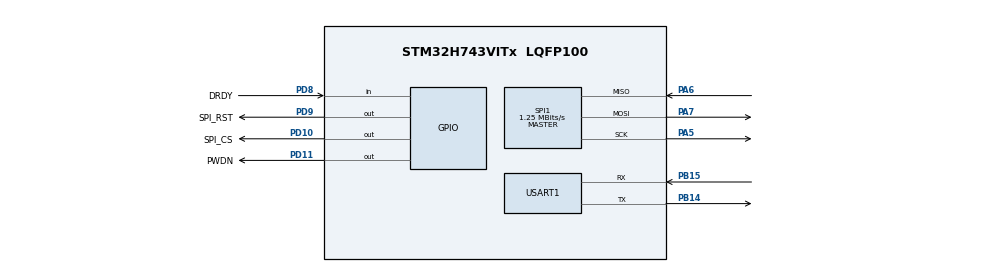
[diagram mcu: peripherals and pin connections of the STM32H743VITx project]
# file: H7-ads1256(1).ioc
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CORTEX_M7.default_mode_Activation=1
Mcu.Family=STM32H7
Mcu.Name=STM32H743VITx
Mcu.Package=LQFP100
NVIC.PriorityGroup=NVIC_PRIORITYGROUP_4
PA13\ (JTMS/SWDIO).Mode=Serial_Wire
PA13\ (JTMS/SWDIO).Signal=DEBUG_JTMS-SWDIO
PA14\ (JTCK/SWCLK).Mode=Serial_Wire
PA14\ (JTCK/SWCLK).Signal=DEBUG_JTCK-SWCLK
PA5.GPIO_Speed=GPIO_SPEED_FREQ_VERY_HIGH
PA5.Mode=Full_Duplex_Master
PA5.Signal=SPI1_SCK
PA6.GPIO_Speed=GPIO_SPEED_FREQ_VERY_HIGH
PA6.Mode=Full_Duplex_Master
PA6.Signal=SPI1_MISO
PA7.GPIO_Speed=GPIO_SPEED_FREQ_VERY_HIGH
PA7.Mode=Full_Duplex_Master
PA7.Signal=SPI1_MOSI
PB14.Mode=Asynchronous
PB14.Signal=USART1_TX
PB15.Mode=Asynchronous
PB15.Signal=USART1_RX
PD10.GPIO_Label=SPI_CS
PD10.GPIO_PuPd=GPIO_NOPULL
PD10.Signal=GPIO_Output
PD11.GPIO_Label=PWDN
PD11.PinState=GPIO_PIN_SET
PD11.Signal=GPIO_Output
PD8.GPIO_Label=DRDY
PD8.GPIO_PuPd=GPIO_NOPULL
PD8.Signal=GPIO_Input
PD9.GPIO_Label=SPI_RST
PD9.GPIO_PuPd=GPIO_PULLUP
PD9.Signal=GPIO_Output
PH0-OSC_IN\ (PH0).Mode=HSE-External-Oscillator
PH0-OSC_IN\ (PH0).Signal=RCC_OSC_IN
PH1-OSC_OUT\ (PH1).Mode=HSE-External-Oscillator
PH1-OSC_OUT\ (PH1).Signal=RCC_OSC_OUT
ProjectManager.HeapSize=0x200
ProjectManager.StackSize=0x400
ProjectManager.TargetToolchain=MDK-ARM V5.32
RCC.ADCFreq_Value=50390625
RCC.APB1Freq_Value=80000000
RCC.APB2Freq_Value=40000000
RCC.APB3Freq_Value=80000000
RCC.APB4Freq_Value=80000000
RCC.CortexFreq_Value=160000000
RCC.D1PPRE=RCC_APB3_DIV2
RCC.D2PPRE1=RCC_APB1_DIV2
RCC.D2PPRE2=RCC_APB2_DIV4
RCC.D3PPRE=RCC_APB4_DIV2
RCC.DIVM1=5
RCC.DIVN1=64
RCC.DIVQ1=4
RCC.HCLKFreq_Value=160000000
RCC.PLL2FRACN=0
RCC.PLL3FRACN=0
RCC.PLLFRACN=0
RCC.PLLSourceVirtual=RCC_PLLSOURCE_HSE
RCC.SYSCLKFreq_VALUE=160000000
RCC.SYSCLKSource=RCC_SYSCLKSOURCE_PLLCLK
RCC.USBFreq_Value=80000000
SPI1.BaudRatePrescaler=SPI_BAUDRATEPRESCALER_64
SPI1.CLKPhase=SPI_PHASE_2EDGE
SPI1.CalculateBaudRate=1.25 MBits/s
SPI1.DataSize=SPI_DATASIZE_8BIT
SPI1.Direction=SPI_DIRECTION_2LINES
SPI1.Mode=SPI_MODE_MASTER
SPI1.NSSPMode=SPI_NSS_PULSE_DISABLE
SPI1.VirtualType=VM_MASTER
USART1.VirtualMode-Asynchronous=VM_ASYNC
VP_MEMORYMAP_VS_MEMORYMAP.Mode=CurAppReg
board=custom

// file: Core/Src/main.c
/* USER CODE BEGIN Header */
/**
  ******************************************************************************
  * @file           : main.c
  * @brief          : Main program body
  ******************************************************************************
  * @attention
  *
  * Copyright (c) 2025 STMicroelectronics.
  * All rights reserved.
  *
  * This software is licensed under terms that can be found in the LICENSE file
  * in the root directory of this software component.
  * If no LICENSE file comes with this software, it is provided AS-IS.
  *
  ******************************************************************************
  */
/* USER CODE END Header */
#include "main.h"
#include "memorymap.h"
#include "spi.h"
#include "usart.h"
#include "gpio.h"

/* USER CODE BEGIN Includes */
#include <stdio.h>
#include "ads.h"
#include <stdlib.h>
/* USER CODE END Includes */

/* USER CODE BEGIN PV */
uint8_t flag =0 ;

    uint8_t channels[] = {AIN0_ADDR, AIN1_ADDR, AIN2_ADDR}; // 要采集的通道
    uint8_t num_channels = sizeof(channels)/sizeof(channels[0]);
    uint32_t sample_count = 1000; // 每个通道采样点数
/* USER CODE END PV */

void SystemClock_Config(void);
static void MPU_Config(void);

int main(void)
{

  /* MPU Configuration--------------------------------------------------------*/
  MPU_Config();

  /* MCU Configuration--------------------------------------------------------*/

  /* Reset of all peripherals, Initializes the Flash interface and the Systick. */
  HAL_Init();

  /* Configure the system clock */
  SystemClock_Config();

  /* Initialize all configured peripherals */
  MX_GPIO_Init();
  MX_SPI1_Init();
  MX_USART1_UART_Init();
  /* USER CODE BEGIN 2 */
//	printf("flag1=%d\r\n",flag);
//  uint8_t DRDY1 = HAL_GPIO_ReadPin(DRDY_GPIO_Port,DRDY_Pin);
//	printf("DRDY1=%d\r\n",DRDY1);
//	ADS1256_Init();
////	ADS1256_Verify_ID();
//	flag=1;
//	printf("flag2=%d\r\n",flag);
//	uint8_t DRDY2 = HAL_GPIO_ReadPin(DRDY_GPIO_Port,DRDY_Pin);
//	printf("DRDY2=%d\r\n",DRDY2);
  float *samples = malloc(num_channels * sample_count * sizeof(float));
    ADS1256_Read_MultiChannels(channels, num_channels, sample_count, samples);

    // 使用数据（示例：打印前5个采样点）
    for (int i = 0; i < 5; i++) {
        printf("采样点 %d: ", i);
        for (int ch = 0; ch < num_channels; ch++) {
            printf("AIN%d=%.4fV ", ch, samples[i * num_channels + ch]);
        }
        printf("\n");
    }

  /* USER CODE END 2 */

  /* Infinite loop */
  /* USER CODE BEGIN WHILE */
  while (1)
  {
//		Read_ADC_Channel(0x08, 0);
    /* USER CODE END WHILE */

  }
}

void SystemClock_Config(void)
{
  RCC_OscInitTypeDef RCC_OscInitStruct = {0};
  RCC_ClkInitTypeDef RCC_ClkInitStruct = {0};

  /** Supply configuration update enable
  */
  HAL_PWREx_ConfigSupply(PWR_LDO_SUPPLY);

  /** Configure the main internal regulator output voltage
  */
  __HAL_PWR_VOLTAGESCALING_CONFIG(PWR_REGULATOR_VOLTAGE_SCALE3);

  while(!__HAL_PWR_GET_FLAG(PWR_FLAG_VOSRDY)) {}

  /** Initializes the RCC Oscillators according to the specified parameters
  * in the RCC_OscInitTypeDef structure.
  */
  RCC_OscInitStruct.OscillatorType = RCC_OSCILLATORTYPE_HSE;
  RCC_OscInitStruct.HSEState = RCC_HSE_ON;
  RCC_OscInitStruct.PLL.PLLState = RCC_PLL_ON;
  RCC_OscInitStruct.PLL.PLLSource = RCC_PLLSOURCE_HSE;
  RCC_OscInitStruct.PLL.PLLM = 5;
  RCC_OscInitStruct.PLL.PLLN = 64;
  RCC_OscInitStruct.PLL.PLLP = 2;
  RCC_OscInitStruct.PLL.PLLQ = 4;
  RCC_OscInitStruct.PLL.PLLR = 2;
  RCC_OscInitStruct.PLL.PLLRGE = RCC_PLL1VCIRANGE_2;
  RCC_OscInitStruct.PLL.PLLVCOSEL = RCC_PLL1VCOWIDE;
  RCC_OscInitStruct.PLL.PLLFRACN = 0;
  if (HAL_RCC_OscConfig(&RCC_OscInitStruct) != HAL_OK)
  {
    Error_Handler();
  }

  /** Initializes the CPU, AHB and APB buses clocks
  */
  RCC_ClkInitStruct.ClockType = RCC_CLOCKTYPE_HCLK|RCC_CLOCKTYPE_SYSCLK
                              |RCC_CLOCKTYPE_PCLK1|RCC_CLOCKTYPE_PCLK2
                              |RCC_CLOCKTYPE_D3PCLK1|RCC_CLOCKTYPE_D1PCLK1;
  RCC_ClkInitStruct.SYSCLKSource = RCC_SYSCLKSOURCE_PLLCLK;
  RCC_ClkInitStruct.SYSCLKDivider = RCC_SYSCLK_DIV1;
  RCC_ClkInitStruct.AHBCLKDivider = RCC_HCLK_DIV1;
  RCC_ClkInitStruct.APB3CLKDivider = RCC_APB3_DIV2;
  RCC_ClkInitStruct.APB1CLKDivider = RCC_APB1_DIV2;
  RCC_ClkInitStruct.APB2CLKDivider = RCC_APB2_DIV4;
  RCC_ClkInitStruct.APB4CLKDivider = RCC_APB4_DIV2;

  if (HAL_RCC_ClockConfig(&RCC_ClkInitStruct, FLASH_LATENCY_3) != HAL_OK)
  {
    Error_Handler();
  }
}

 /* MPU Configuration */

void MPU_Config(void)
{
  MPU_Region_InitTypeDef MPU_InitStruct = {0};

  /* Disables the MPU */
  HAL_MPU_Disable();

  /** Initializes and configures the Region and the memory to be protected
  */
  MPU_InitStruct.Enable = MPU_REGION_ENABLE;
  MPU_InitStruct.Number = MPU_REGION_NUMBER0;
  MPU_InitStruct.BaseAddress = 0x0;
  MPU_InitStruct.Size = MPU_REGION_SIZE_4GB;
  MPU_InitStruct.SubRegionDisable = 0x87;
  MPU_InitStruct.TypeExtField = MPU_TEX_LEVEL0;
  MPU_InitStruct.AccessPermission = MPU_REGION_NO_ACCESS;
  MPU_InitStruct.DisableExec = MPU_INSTRUCTION_ACCESS_DISABLE;
  MPU_InitStruct.IsShareable = MPU_ACCESS_SHAREABLE;
  MPU_InitStruct.IsCacheable = MPU_ACCESS_NOT_CACHEABLE;
  MPU_InitStruct.IsBufferable = MPU_ACCESS_NOT_BUFFERABLE;

  HAL_MPU_ConfigRegion(&MPU_InitStruct);
  /* Enables the MPU */
  HAL_MPU_Enable(MPU_PRIVILEGED_DEFAULT);

}

void Error_Handler(void)
{
  __disable_irq();
  while (1)
  {
  }
}
